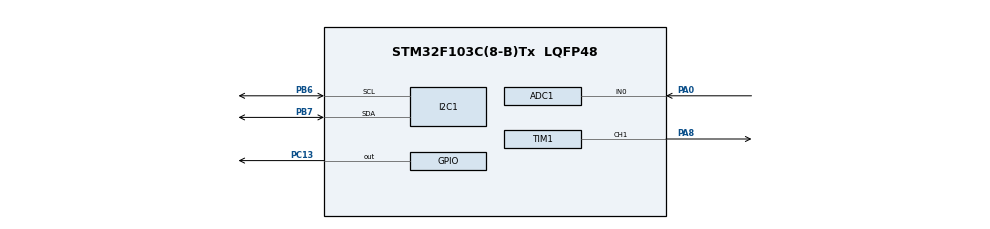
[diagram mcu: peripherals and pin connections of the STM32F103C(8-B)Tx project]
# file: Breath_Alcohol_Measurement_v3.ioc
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ADC1.Channel-0\#ChannelRegularConversion=ADC_CHANNEL_0
ADC1.NbrOfConversionFlag=1
ADC1.Rank-0\#ChannelRegularConversion=1
ADC1.SamplingTime-0\#ChannelRegularConversion=ADC_SAMPLETIME_1CYCLE_5
ADC1.master=1
Mcu.Family=STM32F1
Mcu.Name=STM32F103C(8-B)Tx
Mcu.Package=LQFP48
NVIC.PriorityGroup=NVIC_PRIORITYGROUP_4
PA0-WKUP.Signal=ADCx_IN0
PA8.Signal=S_TIM1_CH1
PB6.Mode=I2C
PB6.Signal=I2C1_SCL
PB7.Mode=I2C
PB7.Signal=I2C1_SDA
PC13-TAMPER-RTC.Signal=GPIO_Output
ProjectManager.HeapSize=0x200
ProjectManager.StackSize=0x400
ProjectManager.TargetToolchain=STM32CubeIDE
RCC.APB1Freq_Value=8000000
RCC.APB2Freq_Value=8000000
SH.ADCx_IN0.0=ADC1_IN0,IN0
SH.S_TIM1_CH1.0=TIM1_CH1,PWM Generation1 CH1
TIM1.Channel-PWM\ Generation1\ CH1=TIM_CHANNEL_1
VP_SYS_VS_ND.Mode=No_Debug
board=custom

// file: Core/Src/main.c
/* USER CODE BEGIN Header */
/**
  ******************************************************************************
  * @file           : main.c
  * @brief          : Main program body
  ******************************************************************************
  * @attention
  *
  * Copyright (c) 2026 STMicroelectronics.
  * All rights reserved.
  *
  * This software is licensed under terms that can be found in the LICENSE file
  * in the root directory of this software component.
  * If no LICENSE file comes with this software, it is provided AS-IS.
  *
  ******************************************************************************
  */
/* USER CODE END Header */
#include "main.h"
#include "lcd.h"
#include <stdio.h>

ADC_HandleTypeDef hadc1;

I2C_HandleTypeDef hi2c1;

TIM_HandleTypeDef htim1;

LiquidCrystal_I2C lcd;

void SystemClock_Config(void);
static void MX_GPIO_Init(void);
static void MX_ADC1_Init(void);
static void MX_I2C1_Init(void);
static void MX_TIM1_Init(void);

int main(void)
{

  /* MCU Configuration--------------------------------------------------------*/

  /* Reset of all peripherals, Initializes the Flash interface and the Systick. */
  HAL_Init();

  /* Configure the system clock */
  SystemClock_Config();

  /* Initialize all configured peripherals */
  MX_GPIO_Init();
  MX_ADC1_Init();
  MX_I2C1_Init();
  MX_TIM1_Init();
  /* USER CODE BEGIN 2 */
  // Khởi động ADC
  HAL_ADC_Start(&hadc1);

  // Khởi động PWM cho buzzer
  HAL_TIM_PWM_Start(&htim1, TIM_CHANNEL_1);

  // Khởi tạo LCD
  LCD_Init(&lcd, &hi2c1, 0x27, 16, 2);
  LCD_Clear(&lcd);
  LCD_Backlight(&lcd);
  /* USER CODE END 2 */

  /* Infinite loop */
  while (1)
  {
	  // Đọc giá trị MQ-3
	  	 	    HAL_ADC_PollForConversion(&hadc1, HAL_MAX_DELAY);
	  	 	    uint32_t adc_value = HAL_ADC_GetValue(&hadc1);

	  	 	    // Quy đổi sang điện áp
	  	 	    float voltage = (adc_value / 4095.0f) * 3.3f;
	  	 	    float bac = voltage * 0.4f; // hệ số giả định, cần hiệu chuẩn

	  	 	    // Hiển thị lên LCD
	  	 	   LCD_SetCursor(&lcd, 0, 0);

	  	 	   char buffer[16];
	  	 	   sprintf(buffer, "BAC: %.2f", bac);
	  	 	   LCD_Print(&lcd, buffer);
	  	 	    // Kiểm tra ngưỡng
	  	 	    if(bac > 0.25f) {
	  	 	      HAL_GPIO_WritePin(GPIOC, GPIO_PIN_13, GPIO_PIN_RESET); // LED ON
	  	 	      __HAL_TIM_SET_COMPARE(&htim1, TIM_CHANNEL_1, 500);     // Buzzer kêu
	  	 	    } else {
	  	 	      HAL_GPIO_WritePin(GPIOC, GPIO_PIN_13, GPIO_PIN_SET);   // LED OFF
	  	 	      __HAL_TIM_SET_COMPARE(&htim1, TIM_CHANNEL_1, 0);       // Buzzer tắt
	  	 	    }

	  	 	    HAL_Delay(500);
  }
}

void SystemClock_Config(void)
{
  RCC_OscInitTypeDef RCC_OscInitStruct = {0};
  RCC_ClkInitTypeDef RCC_ClkInitStruct = {0};
  RCC_PeriphCLKInitTypeDef PeriphClkInit = {0};

  /** Initializes the RCC Oscillators according to the specified parameters
  * in the RCC_OscInitTypeDef structure.
  */
  RCC_OscInitStruct.OscillatorType = RCC_OSCILLATORTYPE_HSI;
  RCC_OscInitStruct.HSIState = RCC_HSI_ON;
  RCC_OscInitStruct.HSICalibrationValue = RCC_HSICALIBRATION_DEFAULT;
  RCC_OscInitStruct.PLL.PLLState = RCC_PLL_NONE;
  if (HAL_RCC_OscConfig(&RCC_OscInitStruct) != HAL_OK)
  {
    Error_Handler();
  }

  /** Initializes the CPU, AHB and APB buses clocks
  */
  RCC_ClkInitStruct.ClockType = RCC_CLOCKTYPE_HCLK|RCC_CLOCKTYPE_SYSCLK
                              |RCC_CLOCKTYPE_PCLK1|RCC_CLOCKTYPE_PCLK2;
  RCC_ClkInitStruct.SYSCLKSource = RCC_SYSCLKSOURCE_HSI;
  RCC_ClkInitStruct.AHBCLKDivider = RCC_SYSCLK_DIV1;
  RCC_ClkInitStruct.APB1CLKDivider = RCC_HCLK_DIV1;
  RCC_ClkInitStruct.APB2CLKDivider = RCC_HCLK_DIV1;

  if (HAL_RCC_ClockConfig(&RCC_ClkInitStruct, FLASH_LATENCY_0) != HAL_OK)
  {
    Error_Handler();
  }
  PeriphClkInit.PeriphClockSelection = RCC_PERIPHCLK_ADC;
  PeriphClkInit.AdcClockSelection = RCC_ADCPCLK2_DIV2;
  if (HAL_RCCEx_PeriphCLKConfig(&PeriphClkInit) != HAL_OK)
  {
    Error_Handler();
  }
}

static void MX_ADC1_Init(void)
{

  ADC_ChannelConfTypeDef sConfig = {0};

  /** Common config
  */
  hadc1.Instance = ADC1;
  hadc1.Init.ScanConvMode = ADC_SCAN_DISABLE;
  hadc1.Init.ContinuousConvMode = DISABLE;
  hadc1.Init.DiscontinuousConvMode = DISABLE;
  hadc1.Init.ExternalTrigConv = ADC_SOFTWARE_START;
  hadc1.Init.DataAlign = ADC_DATAALIGN_RIGHT;
  hadc1.Init.NbrOfConversion = 1;
  if (HAL_ADC_Init(&hadc1) != HAL_OK)
  {
    Error_Handler();
  }

  /** Configure Regular Channel
  */
  sConfig.Channel = ADC_CHANNEL_0;
  sConfig.Rank = ADC_REGULAR_RANK_1;
  sConfig.SamplingTime = ADC_SAMPLETIME_1CYCLE_5;
  if (HAL_ADC_ConfigChannel(&hadc1, &sConfig) != HAL_OK)
  {
    Error_Handler();
  }

}

static void MX_I2C1_Init(void)
{

  hi2c1.Instance = I2C1;
  hi2c1.Init.ClockSpeed = 100000;
  hi2c1.Init.DutyCycle = I2C_DUTYCYCLE_2;
  hi2c1.Init.OwnAddress1 = 0;
  hi2c1.Init.AddressingMode = I2C_ADDRESSINGMODE_7BIT;
  hi2c1.Init.DualAddressMode = I2C_DUALADDRESS_DISABLE;
  hi2c1.Init.OwnAddress2 = 0;
  hi2c1.Init.GeneralCallMode = I2C_GENERALCALL_DISABLE;
  hi2c1.Init.NoStretchMode = I2C_NOSTRETCH_DISABLE;
  if (HAL_I2C_Init(&hi2c1) != HAL_OK)
  {
    Error_Handler();
  }

}

static void MX_TIM1_Init(void)
{

  TIM_MasterConfigTypeDef sMasterConfig = {0};
  TIM_OC_InitTypeDef sConfigOC = {0};
  TIM_BreakDeadTimeConfigTypeDef sBreakDeadTimeConfig = {0};

  htim1.Instance = TIM1;
  htim1.Init.Prescaler = 0;
  htim1.Init.CounterMode = TIM_COUNTERMODE_UP;
  htim1.Init.Period = 65535;
  htim1.Init.ClockDivision = TIM_CLOCKDIVISION_DIV1;
  htim1.Init.RepetitionCounter = 0;
  htim1.Init.AutoReloadPreload = TIM_AUTORELOAD_PRELOAD_DISABLE;
  if (HAL_TIM_PWM_Init(&htim1) != HAL_OK)
  {
    Error_Handler();
  }
  sMasterConfig.MasterOutputTrigger = TIM_TRGO_RESET;
  sMasterConfig.MasterSlaveMode = TIM_MASTERSLAVEMODE_DISABLE;
  if (HAL_TIMEx_MasterConfigSynchronization(&htim1, &sMasterConfig) != HAL_OK)
  {
    Error_Handler();
  }
  sConfigOC.OCMode = TIM_OCMODE_PWM1;
  sConfigOC.Pulse = 0;
  sConfigOC.OCPolarity = TIM_OCPOLARITY_HIGH;
  sConfigOC.OCNPolarity = TIM_OCNPOLARITY_HIGH;
  sConfigOC.OCFastMode = TIM_OCFAST_DISABLE;
  sConfigOC.OCIdleState = TIM_OCIDLESTATE_RESET;
  sConfigOC.OCNIdleState = TIM_OCNIDLESTATE_RESET;
  if (HAL_TIM_PWM_ConfigChannel(&htim1, &sConfigOC, TIM_CHANNEL_1) != HAL_OK)
  {
    Error_Handler();
  }
  sBreakDeadTimeConfig.OffStateRunMode = TIM_OSSR_DISABLE;
  sBreakDeadTimeConfig.OffStateIDLEMode = TIM_OSSI_DISABLE;
  sBreakDeadTimeConfig.LockLevel = TIM_LOCKLEVEL_OFF;
  sBreakDeadTimeConfig.DeadTime = 0;
  sBreakDeadTimeConfig.BreakState = TIM_BREAK_DISABLE;
  sBreakDeadTimeConfig.BreakPolarity = TIM_BREAKPOLARITY_HIGH;
  sBreakDeadTimeConfig.AutomaticOutput = TIM_AUTOMATICOUTPUT_DISABLE;
  if (HAL_TIMEx_ConfigBreakDeadTime(&htim1, &sBreakDeadTimeConfig) != HAL_OK)
  {
    Error_Handler();
  }
  HAL_TIM_MspPostInit(&htim1);

}

static void MX_GPIO_Init(void)
{
  GPIO_InitTypeDef GPIO_InitStruct = {0};

  /* GPIO Ports Clock Enable */
  __HAL_RCC_GPIOC_CLK_ENABLE();
  __HAL_RCC_GPIOA_CLK_ENABLE();
  __HAL_RCC_GPIOB_CLK_ENABLE();

  /*Configure GPIO pin Output Level */
  HAL_GPIO_WritePin(GPIOC, GPIO_PIN_13, GPIO_PIN_RESET);

  /*Configure GPIO pin : PC13 */
  GPIO_InitStruct.Pin = GPIO_PIN_13;
  GPIO_InitStruct.Mode = GPIO_MODE_OUTPUT_PP;
  GPIO_InitStruct.Pull = GPIO_NOPULL;
  GPIO_InitStruct.Speed = GPIO_SPEED_FREQ_LOW;
  HAL_GPIO_Init(GPIOC, &GPIO_InitStruct);

}

void Error_Handler(void)
{
  __disable_irq();
  while (1)
  {
  }
}
